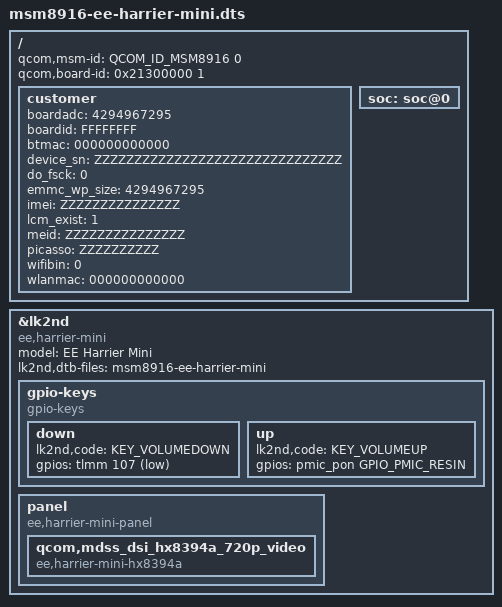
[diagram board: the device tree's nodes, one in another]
// SPDX-License-Identifier: BSD-3-Clause

#include <skeleton64.dtsi>
#include <lk2nd.dtsi>

/ {
	qcom,msm-id = <QCOM_ID_MSM8916 0>;
	qcom,board-id = <0x21300000 1>;

	/*
	 * HACK: EE / BenQ's bootloader expects these nodes to exist in
	 * the dtb as it tries to populate these nodes. Without the
	 * nodes existing the bootloader will crash or invalidate the
	 * FDT.
	 */

	customer {
		boardadc = "4294967295";
		boardid = "FFFFFFFF";
		btmac = "000000000000";
		device_sn = "ZZZZZZZZZZZZZZZZZZZZZZZZZZZZZZZ";
		do_fsck = "0";
		emmc_wp_size = "4294967295";
		imei = "ZZZZZZZZZZZZZZZ";
		lcm_exist = "1";
		meid = "ZZZZZZZZZZZZZZZ";
		picasso = "ZZZZZZZZZZ";
		wifibin = "0";
		wlanmac = "000000000000";
	};

	soc: soc@0 {
	};
};

&lk2nd {
	model = "EE Harrier Mini";
	compatible = "ee,harrier-mini";

	lk2nd,dtb-files = "msm8916-ee-harrier-mini";

	gpio-keys {
		compatible = "gpio-keys";

		down {
			lk2nd,code = <KEY_VOLUMEDOWN>;
			gpios = <&tlmm 107 (GPIO_ACTIVE_LOW | GPIO_PULL_UP)>;
		};

		up {
			lk2nd,code = <KEY_VOLUMEUP>;
			gpios = <&pmic_pon GPIO_PMIC_RESIN 0>;
		};
	};

	panel {
		compatible = "ee,harrier-mini-panel", "lk2nd,panel";

		qcom,mdss_dsi_hx8394a_720p_video {
			compatible = "ee,harrier-mini-hx8394a";
		};
	};
};
